VERSION ""

NS_ :

BS_:

BU_: ECU_ENGINE ECU_BODY ECU_GATEWAY

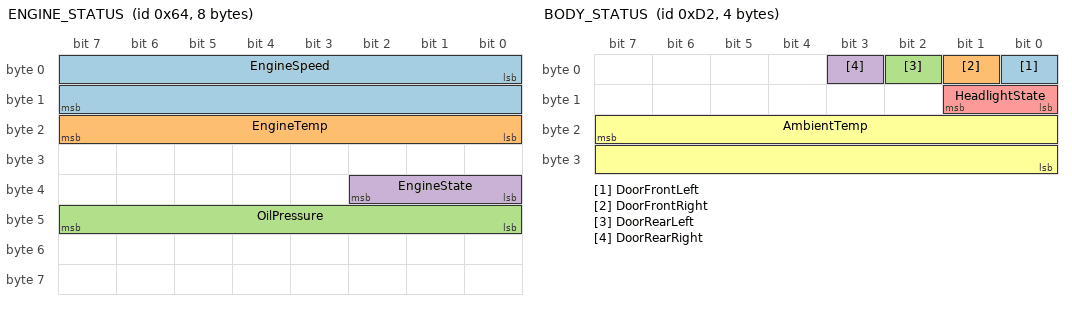
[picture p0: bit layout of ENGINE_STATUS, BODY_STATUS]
BO_ 100 ENGINE_STATUS: 8 ECU_ENGINE
 SG_ EngineSpeed : 0|16@1+ (0.5,0) [0|32767.5] "rpm" ECU_GATEWAY
 SG_ EngineTemp : 16|8@1- (1,-40) [-40|215] "degC" ECU_GATEWAY
 SG_ OilPressure : 40|8@1+ (1,0) [0|255] "kPa" ECU_GATEWAY
 SG_ EngineState : 32|3@1+ (1,0) [0|4] "" ECU_GATEWAY,ECU_BODY

BO_ 210 BODY_STATUS: 4 ECU_BODY
 SG_ DoorFrontLeft : 0|1@1+ (1,0) [0|1] "" ECU_GATEWAY
 SG_ DoorFrontRight : 1|1@1+ (1,0) [0|1] "" ECU_GATEWAY
 SG_ DoorRearLeft : 2|1@1+ (1,0) [0|1] "" ECU_GATEWAY
 SG_ DoorRearRight : 3|1@1+ (1,0) [0|1] "" ECU_GATEWAY
 SG_ HeadlightState : 8|2@1+ (1,0) [0|2] "" ECU_GATEWAY
 SG_ AmbientTemp : 23|16@0- (0.1,-40) [-40|85] "degC" ECU_GATEWAY

BO_ 400 DIAG_REQUEST: 8 ECU_GATEWAY
 SG_ DiagMux M : 0|8@1+ (1,0) [0|255] "" ECU_ENGINE,ECU_BODY
 SG_ DiagParam1 m0 : 8|16@1+ (1,0) [0|65535] "" ECU_ENGINE
 SG_ DiagParam2 m1 : 8|16@1+ (1,0) [0|65535] "" ECU_BODY

BO_ 500 BATTERY_STATUS: 4 ECU_BODY
 SG_ BatteryVoltage : 0|16@1+ (0.01,0) [0|20] "V" ECU_GATEWAY
 SG_ BatteryCurrent : 16|16@1- (0.1,0) [-3200|3200] "A" ECU_GATEWAY

BA_DEF_ BO_ "GenMsgCycleTime" INT 0 10000;
BA_DEF_DEF_ "GenMsgCycleTime" 100;
BA_ "GenMsgCycleTime" BO_ 210 500;

VAL_ 100 EngineState 0 "Off" 1 "Cranking" 2 "Running" 3 "Overheat" 4 "Fault" ;
VAL_ 210 HeadlightState 0 "Off" 1 "LowBeam" 2 "HighBeam" 3 "Flashing" ;
